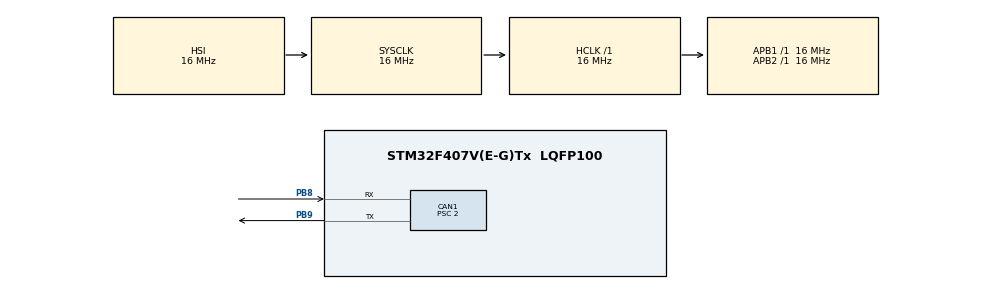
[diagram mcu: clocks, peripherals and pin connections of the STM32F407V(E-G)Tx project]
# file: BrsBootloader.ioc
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CAN1.BS1=CAN_BS1_6TQ
CAN1.CalculateBaudRate=1000000
CAN1.CalculateTimeBit=1000
CAN1.CalculateTimeQuantum=125.0
CAN1.Prescaler=2
Mcu.Family=STM32F4
Mcu.Name=STM32F407V(E-G)Tx
Mcu.Package=LQFP100
NVIC.CAN1_RX0_IRQn=true\:0\:0\:false\:false\:true\:true\:true\:true
NVIC.PriorityGroup=NVIC_PRIORITYGROUP_4
PA13.Mode=Serial_Wire
PA13.Signal=SYS_JTMS-SWDIO
PA14.Mode=Serial_Wire
PA14.Signal=SYS_JTCK-SWCLK
PB8.Mode=CAN_Activate
PB8.Signal=CAN1_RX
PB9.Mode=CAN_Activate
PB9.Signal=CAN1_TX
ProjectManager.HeapSize=0x200
ProjectManager.StackSize=0x400
ProjectManager.TargetToolchain=STM32CubeIDE
RCC.48MHZClocksFreq_Value=48000000
RCC.AHBFreq_Value=16000000
RCC.APB1Freq_Value=16000000
RCC.APB1TimFreq_Value=16000000
RCC.APB2Freq_Value=16000000
RCC.APB2TimFreq_Value=16000000
RCC.CortexFreq_Value=16000000
RCC.HCLKFreq_Value=16000000
RCC.HSE_VALUE=25000000
RCC.HSI_VALUE=16000000
RCC.LSE_VALUE=32768
RCC.SYSCLKFreq_VALUE=16000000
RCC.VCOOutputFreq_Value=192000000
board=custom

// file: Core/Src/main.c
/* USER CODE BEGIN Header */
/**
  ******************************************************************************
  * @file           : main.c
  * @brief          : Main program body
  ******************************************************************************
  * @attention
  *
  * Copyright (c) 2023 STMicroelectronics.
  * All rights reserved.
  *
  * This software is licensed under terms that can be found in the LICENSE file
  * in the root directory of this software component.
  * If no LICENSE file comes with this software, it is provided AS-IS.
  *
  ******************************************************************************
  */
/* USER CODE END Header */
#include "main.h"

/* USER CODE BEGIN Includes */

#include <stdio.h>
#include "brs_can_flash.h"

/* USER CODE END Includes */

/* USER CODE BEGIN PTD */

typedef void (*pFunction)(void);

/* USER CODE END PTD */

/* USER CODE BEGIN PD */

#define FLASH_APP_ADDR 0x8008000

/* USER CODE END PD */

CAN_HandleTypeDef hcan1;

/* USER CODE BEGIN PV */

CAN_TxHeaderTypeDef canTxHeader;
CAN_RxHeaderTypeDef canRxHeader;

uint8_t canTxData[8];
uint8_t canRxData[8];

uint32_t canTxMailbox;

/* USER CODE END PV */

void SystemClock_Config(void);
static void MX_GPIO_Init(void);
static void MX_CAN1_Init(void);

/* USER CODE BEGIN 0 */

void GoToApp()
{
	uint32_t jumpAddress;
	pFunction jumpToApp;

	// Check if there is something "installed" in the app FLASH region
	//if(((*(uint32_t*) FLASH_APP_ADDR) & 0x2FFE0000) == 0x20000000)
	if((*(uint32_t*) FLASH_APP_ADDR) != 0xFFFFFFFF)
	{
		printf("Application found. Preparing to jump.\n");

		// Jump to the application
		jumpAddress = *(uint32_t *)(FLASH_APP_ADDR + 4);
		jumpToApp = (pFunction)jumpAddress;

		// SysTick
		HAL_SuspendTick();
		SysTick->VAL = 0;
		SysTick->LOAD = 0;
		__disable_irq();

		// Init app stack ptr
		__set_MSP(*(uint32_t *)FLASH_APP_ADDR);

		// Jump
		jumpToApp();
	}
	else // If no app installed
	{
		printf("No application found.\n");
	}
}

uint8_t flashRx = 0;

void HAL_CAN_RxFifo0MsgPendingCallback(CAN_HandleTypeDef* hcan)
{
	if (HAL_CAN_GetRxMessage(hcan, CAN_RX_FIFO0, &canRxHeader, canRxData) != HAL_OK)
	{
		printf("Failed to read CAN1 RX\n");
		Error_Handler();
	}

	const uint32_t msgId = canRxHeader.StdId;

//	printf("ID: 0x%x\n", (unsigned int)msgId);

	// If message is part of can-flash-protocol
	if (msgId == CAN_MSG_ID_FLASH_INIT || msgId == CAN_MSG_ID_FLASH_DATA)
	{
		// Notify main loop that new flash relevant message has been received
		flashRx = 1;
	}
}

int _write(int file, char* ptr, int len)
{
	for (int i = 0; i < len; i++)
	{
		ITM_SendChar(*ptr++);
	}
	return len;
}

/* USER CODE END 0 */

int main(void)
{

  /* MCU Configuration--------------------------------------------------------*/

  /* Reset of all peripherals, Initializes the Flash interface and the Systick. */
  HAL_Init();

  /* USER CODE BEGIN Init */

  printf("Starting bootloader.\n");

  /* USER CODE END Init */

  /* Configure the system clock */
  SystemClock_Config();

  /* Initialize all configured peripherals */
  MX_GPIO_Init();
  MX_CAN1_Init();
  /* USER CODE BEGIN 2 */

  CAN_FilterTypeDef canfilterconfig;
  canfilterconfig.FilterActivation = CAN_FILTER_ENABLE;
  canfilterconfig.FilterBank = 18;  // which filter bank to use from the assigned ones
  canfilterconfig.FilterFIFOAssignment = CAN_FILTER_FIFO0;
  canfilterconfig.FilterIdHigh = 0x0000;
  canfilterconfig.FilterIdLow = 0;
  canfilterconfig.FilterMaskIdHigh = 0x0000;
  canfilterconfig.FilterMaskIdLow = 0x0000;
  canfilterconfig.FilterMode = CAN_FILTERMODE_IDMASK;
  canfilterconfig.FilterScale = CAN_FILTERSCALE_32BIT;
  canfilterconfig.SlaveStartFilterBank = 20;  // how many filters to assign to the CAN1 (master can)
  HAL_CAN_ConfigFilter(&hcan1, &canfilterconfig);

  while(HAL_CAN_Start(&hcan1) != HAL_OK)
  {
	  printf("Failed to start CAN1\n");
	  HAL_Delay(10);
  }

  HAL_CAN_ActivateNotification(&hcan1, CAN_IT_RX_FIFO0_MSG_PENDING);

  canTxHeader.StdId = 0x42;
  canTxHeader.ExtId = 0x00;
  canTxHeader.DLC = 8;
  canTxHeader.IDE = CAN_ID_STD;
  canTxHeader.RTR = CAN_RTR_DATA;

  for (int i = 0; i < 8; i++)
  {
	  canTxData[i] = i + 1;
  }

  /* USER CODE END 2 */

  /* Infinite loop */
  /* USER CODE BEGIN WHILE */

  printf("Entering bootloader main loop.\n");

  while (1)
  {
    /* USER CODE END WHILE */

    /* USER CODE BEGIN 3 */

//	GoToApp();
	// If can msg has been received
    if (flashRx == 1)
    {
    	// Use brs can flash protocol
    	process_can(&canRxHeader, canRxData, &canTxHeader, canTxData);

    	// Send reply
    	HAL_CAN_AddTxMessage(&hcan1, &canTxHeader, canTxData, &canTxMailbox);

    	// Reset status
    	flashRx = 0;
    }
  }

  printf("Ending bootloader.\n");

  /* USER CODE END 3 */
}

void SystemClock_Config(void)
{
  RCC_OscInitTypeDef RCC_OscInitStruct = {0};
  RCC_ClkInitTypeDef RCC_ClkInitStruct = {0};

  /** Configure the main internal regulator output voltage
  */
  __HAL_RCC_PWR_CLK_ENABLE();
  __HAL_PWR_VOLTAGESCALING_CONFIG(PWR_REGULATOR_VOLTAGE_SCALE1);

  /** Initializes the RCC Oscillators according to the specified parameters
  * in the RCC_OscInitTypeDef structure.
  */
  RCC_OscInitStruct.OscillatorType = RCC_OSCILLATORTYPE_HSI;
  RCC_OscInitStruct.HSIState = RCC_HSI_ON;
  RCC_OscInitStruct.HSICalibrationValue = RCC_HSICALIBRATION_DEFAULT;
  RCC_OscInitStruct.PLL.PLLState = RCC_PLL_NONE;
  if (HAL_RCC_OscConfig(&RCC_OscInitStruct) != HAL_OK)
  {
    Error_Handler();
  }

  /** Initializes the CPU, AHB and APB buses clocks
  */
  RCC_ClkInitStruct.ClockType = RCC_CLOCKTYPE_HCLK|RCC_CLOCKTYPE_SYSCLK
                              |RCC_CLOCKTYPE_PCLK1|RCC_CLOCKTYPE_PCLK2;
  RCC_ClkInitStruct.SYSCLKSource = RCC_SYSCLKSOURCE_HSI;
  RCC_ClkInitStruct.AHBCLKDivider = RCC_SYSCLK_DIV1;
  RCC_ClkInitStruct.APB1CLKDivider = RCC_HCLK_DIV1;
  RCC_ClkInitStruct.APB2CLKDivider = RCC_HCLK_DIV1;

  if (HAL_RCC_ClockConfig(&RCC_ClkInitStruct, FLASH_LATENCY_0) != HAL_OK)
  {
    Error_Handler();
  }
}

static void MX_CAN1_Init(void)
{

  hcan1.Instance = CAN1;
  hcan1.Init.Prescaler = 2;
  hcan1.Init.Mode = CAN_MODE_NORMAL;
  hcan1.Init.SyncJumpWidth = CAN_SJW_1TQ;
  hcan1.Init.TimeSeg1 = CAN_BS1_6TQ;
  hcan1.Init.TimeSeg2 = CAN_BS2_1TQ;
  hcan1.Init.TimeTriggeredMode = DISABLE;
  hcan1.Init.AutoBusOff = DISABLE;
  hcan1.Init.AutoWakeUp = DISABLE;
  hcan1.Init.AutoRetransmission = DISABLE;
  hcan1.Init.ReceiveFifoLocked = DISABLE;
  hcan1.Init.TransmitFifoPriority = DISABLE;
  if (HAL_CAN_Init(&hcan1) != HAL_OK)
  {
    Error_Handler();
  }

}

static void MX_GPIO_Init(void)
{

  /* GPIO Ports Clock Enable */
  __HAL_RCC_GPIOA_CLK_ENABLE();
  __HAL_RCC_GPIOB_CLK_ENABLE();

}

void Error_Handler(void)
{
  __disable_irq();
  while (1)
  {
  }
}
